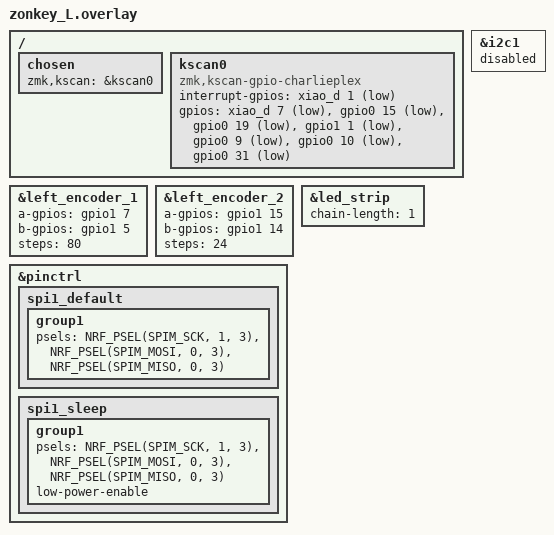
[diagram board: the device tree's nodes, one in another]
#include "zonkey.dtsi"

/ {
    chosen {
        // 【重要】ZMKにこの新しいチャーリープレックス機構を使うよう指示
        zmk,kscan = &kscan0;
    };

    kscan0: kscan0 {
        compatible = "zmk,kscan-gpio-charlieplex";
        interrupt-gpios = <&xiao_d 1 (GPIO_ACTIVE_LOW | GPIO_PULL_UP)>;
        
        // 【重要】すべてのピンに GPIO_PULL_UP を追加
        gpios = <&xiao_d 7 (GPIO_ACTIVE_LOW | GPIO_PULL_UP)>,
                <&gpio0 15 (GPIO_ACTIVE_LOW | GPIO_PULL_UP)>,
                <&gpio0 19 (GPIO_ACTIVE_LOW | GPIO_PULL_UP)>,
                <&gpio1 1  (GPIO_ACTIVE_LOW | GPIO_PULL_UP)>,
                <&gpio0 9  (GPIO_ACTIVE_LOW | GPIO_PULL_UP)>,
                <&gpio0 10 (GPIO_ACTIVE_LOW | GPIO_PULL_UP)>,
                <&gpio0 31 (GPIO_ACTIVE_LOW | GPIO_PULL_UP)>;
    };
};

// --- 以下、エンコーダやpinctrlの設定はそのまま維持 ---
&left_encoder_1 {
    a-gpios = <&gpio1 7 (GPIO_ACTIVE_HIGH | GPIO_PULL_UP)>;
    b-gpios = <&gpio1 5 (GPIO_ACTIVE_HIGH | GPIO_PULL_UP)>;
    steps = <80>;
    status = "okay";
};

&left_encoder_2 {
    a-gpios = <&gpio1 15 (GPIO_ACTIVE_HIGH | GPIO_PULL_UP)>;
    b-gpios = <&gpio1 14 (GPIO_ACTIVE_HIGH | GPIO_PULL_UP)>;
    steps = <24>;
    status = "okay";
};

&pinctrl {
    spi1_default: spi1_default {
        group1 {
            psels = <NRF_PSEL(SPIM_SCK, 1, 3)>,
                    <NRF_PSEL(SPIM_MOSI, 0, 3)>,
                    <NRF_PSEL(SPIM_MISO, 0, 3)>;
        };
    };

    spi1_sleep: spi1_sleep {
        group1 {
            psels = <NRF_PSEL(SPIM_SCK, 1, 3)>,
                    <NRF_PSEL(SPIM_MOSI, 0, 3)>,
                    <NRF_PSEL(SPIM_MISO, 0, 3)>;
            low-power-enable;
        };
    };
};

&led_strip {
    status = "okay";
    chain-length = <1>;
};

&i2c1 {
    status = "disabled";
};
